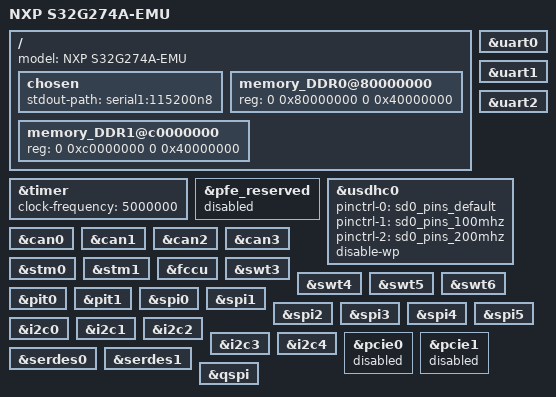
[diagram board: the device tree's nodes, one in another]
// SPDX-License-Identifier: GPL-2.0-or-later OR MIT
/*
 * Copyright 2017-2024 NXP
 */

/dts-v1/;
#include "s32g2.dtsi"

/* Emulator has less than 1GB of RAM, remove reserved memory above this limit */
/delete-node/ &pci_shared_memory0;
/delete-node/ &pci_shared_memory1;

/ {
	model = "NXP S32G274A-EMU";

	chosen {
		stdout-path = "serial1:115200n8";
	};

	memory_DDR0@80000000 {
		device_type = "memory";
		reg = <0 0x80000000 0 0x40000000>;
	};

	memory_DDR1@c0000000 {
		device_type = "memory";
		reg = <0 0xc0000000 0 0x40000000>;
	};
};

&uart0 {
	/delete-property/ dmas;
	/delete-property/ dma-names;
};

&uart1 {
	/delete-property/ dmas;
	/delete-property/ dma-names;
};

&uart2 {
	/delete-property/ dmas;
	/delete-property/ dma-names;
};

&timer {
	clock-frequency = <5000000>;
};

&pfe_reserved  {
	status = "disabled";
};

&usdhc0 {
	pinctrl-names = "default", "state_100mhz", "state_200mhz";
	pinctrl-0 = <&sd0_pins_default>;
	pinctrl-1 = <&sd0_pins_100mhz>;
	pinctrl-2 = <&sd0_pins_200mhz>;
	disable-wp;
	status = "okay";
};

&can0 {
	status = "okay";
};

&can1 {
	status = "okay";
};

&can2 {
	status = "okay";
};

&can3 {
	status = "okay";
};

&stm0 {
	status = "okay";
};

&stm1 {
	status = "okay";
};

&fccu {
	status = "okay";
};

&swt3 {
	status = "okay";
};

&swt4 {
	status = "okay";
};

&swt5 {
	status = "okay";
};

&swt6 {
	status = "okay";
};

&pit0 {
	status = "okay";
};

&pit1 {
	status = "okay";
};

&spi0 {
	status = "okay";
};

&spi1 {
	status = "okay";
};

&spi2 {
	status = "okay";
};

&spi3 {
	status = "okay";
};

&spi4 {
	status = "okay";
};

&spi5 {
	status = "okay";
};

&i2c0 {
	status = "okay";
};

&i2c1 {
	status = "okay";
};

&i2c2 {
	status = "okay";
};

&i2c3 {
	status = "okay";
};

&i2c4 {
	status = "okay";
};

&pcie0 {
	/delete-property/ shared-mem;
	status = "disabled";
};

&pcie1 {
	/delete-property/ shared-mem;
	status = "disabled";
};

&serdes0 {
	status = "okay";
};

&serdes1 {
	status = "okay";
};

&qspi {
	status = "okay";
};
